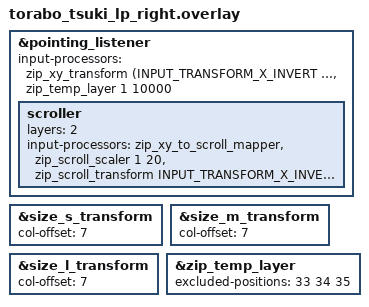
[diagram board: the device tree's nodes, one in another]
#include "torabo_tsuki_lp.dtsi"
#include <input/processors.dtsi>
#include <dt-bindings/zmk/input_transform.h>

&pointing_listener {
    input-processors = <
        &zip_xy_transform (INPUT_TRANSFORM_X_INVERT | INPUT_TRANSFORM_Y_INVERT)
        &zip_temp_layer 1 10000                                                  //追記: AMLのレイヤーとタイムアウトする時間 動作確認済
    >;

    scroller {                                            //追記: スクロールレイヤー 動作確認済
        layers = <2>;                                     //レイヤー2をスクロールレイヤーに設定
        input-processors = <                              //    スクロールレイヤー移行後にスクロールが有効になるまでの余白時間が長く感じたため、
            &zip_xy_to_scroll_mapper                      //    別途keymap.keymapにbehaviorを追加し、それを介してスクロールレイヤーに入ることで解消
            &zip_scroll_scaler 1 20                       //スクロール速度 1/20、デフォのスクロールはやすぎ
            &zip_scroll_transform INPUT_TRANSFORM_X_INVERT    //X軸逆転、横スクロールが左右逆だったため
        >;                                                //
    };                                                    //追記: ここまで
};

&size_s_transform {
    col-offset = <7>;
};

&size_m_transform {
    col-offset = <7>;
};

&size_l_transform {
    col-offset = <7>;
};

&zip_temp_layer {                //追記: AML抜け除外 動作確認済
    excluded-positions = <       //    除外するキーを設定することで、
        33 // J                  //    それ以外のキーを押すとAMLから抜けるようになる
        34 // K                  //
        35 // L                  //
    >;                           //
};                               //追記: ここまで
